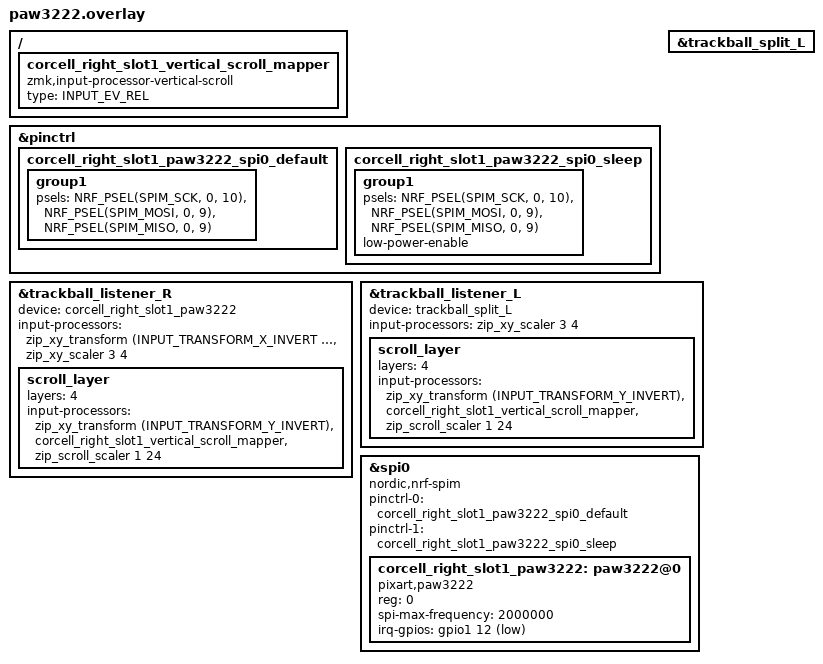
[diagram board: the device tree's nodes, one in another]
#include <dt-bindings/pinctrl/nrf-pinctrl.h>
#include <dt-bindings/zmk/input_transform.h>
#include <zephyr/dt-bindings/input/input-event-codes.h>
#include <input/processors.dtsi>

&pinctrl {
    corcell_right_slot1_paw3222_spi0_default: corcell_right_slot1_paw3222_spi0_default {
        group1 {
            psels = <NRF_PSEL(SPIM_SCK, 0, 10)>,
                    <NRF_PSEL(SPIM_MOSI, 0, 9)>,
                    <NRF_PSEL(SPIM_MISO, 0, 9)>;
        };
    };

    corcell_right_slot1_paw3222_spi0_sleep: corcell_right_slot1_paw3222_spi0_sleep {
        group1 {
            psels = <NRF_PSEL(SPIM_SCK, 0, 10)>,
                    <NRF_PSEL(SPIM_MOSI, 0, 9)>,
                    <NRF_PSEL(SPIM_MISO, 0, 9)>;
            low-power-enable;
        };
    };
};

/ {
    corcell_right_slot1_vertical_scroll_mapper: corcell_right_slot1_vertical_scroll_mapper {
        compatible = "zmk,input-processor-vertical-scroll";
        #input-processor-cells = <0>;
        type = <INPUT_EV_REL>;
    };
};

&trackball_listener_R {
    status = "okay";
    device = <&corcell_right_slot1_paw3222>;
    input-processors =
        <&zip_xy_transform (INPUT_TRANSFORM_X_INVERT | INPUT_TRANSFORM_Y_INVERT)>,
        <&zip_xy_scaler 3 4>;

    scroll_layer {
        layers = <4>;
        input-processors =
            <&zip_xy_transform (INPUT_TRANSFORM_Y_INVERT)>,
            <&corcell_right_slot1_vertical_scroll_mapper>,
            <&zip_scroll_scaler 1 24>;
    };
};

/* Input relayed from the left half. */
&trackball_split_L {
    status = "okay";
};

&trackball_listener_L {
    status = "okay";
    device = <&trackball_split_L>;
    /*
     * The left FPC slot is the mirror image of the right one, so the same
     * module sits rotated 180 degrees and needs no inversion.
     */
    input-processors =
        <&zip_xy_scaler 3 4>;

    scroll_layer {
        layers = <4>;
        input-processors =
            <&zip_xy_transform (INPUT_TRANSFORM_Y_INVERT)>,
            <&corcell_right_slot1_vertical_scroll_mapper>,
            <&zip_scroll_scaler 1 24>;
    };
};

&spi0 {
    status = "okay";
    compatible = "nordic,nrf-spim";
    pinctrl-0 = <&corcell_right_slot1_paw3222_spi0_default>;
    pinctrl-1 = <&corcell_right_slot1_paw3222_spi0_sleep>;
    pinctrl-names = "default", "sleep";

    corcell_right_slot1_paw3222: paw3222@0 {
        compatible = "pixart,paw3222";
        reg = <0>;
        status = "okay";
        spi-max-frequency = <2000000>;
        irq-gpios = <&gpio1 12 (GPIO_ACTIVE_LOW | GPIO_PULL_UP)>;
    };
};
